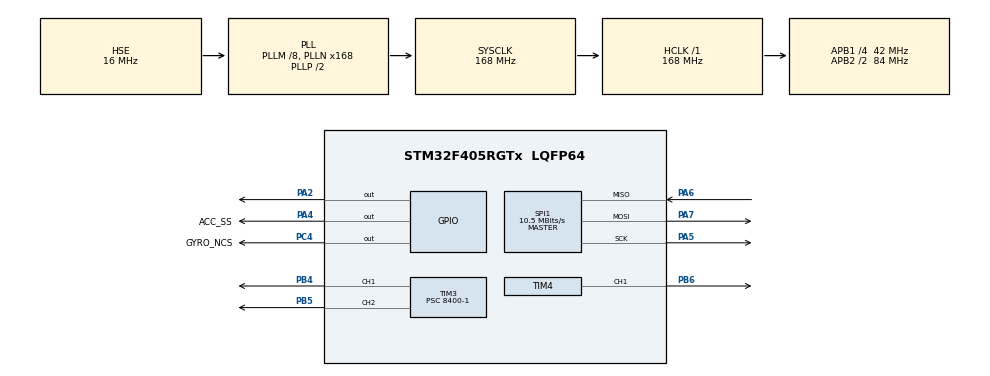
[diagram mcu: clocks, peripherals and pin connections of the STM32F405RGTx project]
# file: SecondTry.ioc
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Mcu.Family=STM32F4
Mcu.Name=STM32F405RGTx
Mcu.Package=LQFP64
NVIC.PriorityGroup=NVIC_PRIORITYGROUP_4
PA13.Mode=Trace_Asynchronous_SW
PA13.Signal=SYS_JTMS-SWDIO
PA14.Mode=Trace_Asynchronous_SW
PA14.Signal=SYS_JTCK-SWCLK
PA2.Signal=GPIO_Output
PA4.GPIO_Label=ACC_SS
PA4.Signal=GPIO_Output
PA5.Mode=Full_Duplex_Master
PA5.Signal=SPI1_SCK
PA6.Mode=Full_Duplex_Master
PA6.Signal=SPI1_MISO
PA7.Mode=Full_Duplex_Master
PA7.Signal=SPI1_MOSI
PB3.Mode=Trace_Asynchronous_SW
PB3.Signal=SYS_JTDO-SWO
PB4.Signal=S_TIM3_CH1
PB5.Signal=S_TIM3_CH2
PB6.Signal=S_TIM4_CH1
PC4.GPIO_Label=GYRO_NCS
PC4.Signal=GPIO_Output
PH0-OSC_IN.Mode=HSE-External-Oscillator
PH0-OSC_IN.Signal=RCC_OSC_IN
PH1-OSC_OUT.Mode=HSE-External-Oscillator
PH1-OSC_OUT.Signal=RCC_OSC_OUT
ProjectManager.HeapSize=0x200
ProjectManager.StackSize=0x400
ProjectManager.TargetToolchain=STM32CubeIDE
RCC.48MHZClocksFreq_Value=48000000
RCC.AHBFreq_Value=168000000
RCC.APB1CLKDivider=RCC_HCLK_DIV4
RCC.APB1Freq_Value=42000000
RCC.APB1TimFreq_Value=84000000
RCC.APB2CLKDivider=RCC_HCLK_DIV2
RCC.APB2Freq_Value=84000000
RCC.APB2TimFreq_Value=168000000
RCC.CortexFreq_Value=168000000
RCC.HCLKFreq_Value=168000000
RCC.HSE_VALUE=16000000
RCC.HSI_VALUE=16000000
RCC.LSE_VALUE=32768
RCC.PLLM=8
RCC.PLLN=168
RCC.PLLQ=7
RCC.PLLSourceVirtual=RCC_PLLSOURCE_HSE
RCC.SYSCLKFreq_VALUE=168000000
RCC.SYSCLKSource=RCC_SYSCLKSOURCE_PLLCLK
RCC.VCOOutputFreq_Value=336000000
SH.S_TIM3_CH1.0=TIM3_CH1,PWM Generation1 CH1
SH.S_TIM3_CH2.0=TIM3_CH2,PWM Generation2 CH2
SH.S_TIM4_CH1.0=TIM4_CH1,PWM Generation1 CH1
SPI1.BaudRatePrescaler=SPI_BAUDRATEPRESCALER_8
SPI1.CalculateBaudRate=10.5 MBits/s
SPI1.Direction=SPI_DIRECTION_2LINES
SPI1.Mode=SPI_MODE_MASTER
SPI1.VirtualType=VM_MASTER
TIM3.Channel-PWM\ Generation1\ CH1=TIM_CHANNEL_1
TIM3.Channel-PWM\ Generation2\ CH2=TIM_CHANNEL_2
TIM3.Period=100-1
TIM3.Prescaler=8400-1
TIM4.Channel-PWM\ Generation1\ CH1=TIM_CHANNEL_1
TIM4.Period=100-1
TIM4.Prescaler=8400-1
board=custom

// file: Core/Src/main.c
/* USER CODE BEGIN Header */
/**
  ******************************************************************************
  * @file           : main.c
  * @brief          : Main program body
  ******************************************************************************
  * @attention
  *
  * Copyright (c) 2024 STMicroelectronics.
  * All rights reserved.
  *
  * This software is licensed under terms that can be found in the LICENSE file
  * in the root directory of this software component.
  * If no LICENSE file comes with this software, it is provided AS-IS.
  *
  ******************************************************************************
  */
/* USER CODE END Header */
#include "main.h"
SPI_HandleTypeDef hspi1;

TIM_HandleTypeDef htim3;
TIM_HandleTypeDef htim4;

void SystemClock_Config(void);
static void MX_GPIO_Init(void);
static void MX_SPI1_Init(void);
static void MX_TIM3_Init(void);
static void MX_TIM4_Init(void);

// Define your pin connections
#define ENABLE_Pin GPIO_PIN_7
#define ENABLE_GPIO_Port GPIOA
#define STEP_Pin GPIO_PIN_8
#define STEP_GPIO_Port GPIOA
#define DIR_Pin GPIO_PIN_9
#define DIR_GPIO_Port GPIOA
#define MS_Pin GPIO_PIN_10
#define MS_GPIO_Port GPIOA

// Define pins
#define PWM_Pin GPIO_PIN_6
#define PWM_GPIO_Port GPIOC
#define R1_EN_Pin GPIO_PIN_11
#define R1_EN_GPIO_Port GPIOC
#define R1_IS_Pin GPIO_PIN_10
#define R1_IS_GPIO_Port GPIOC

// Function to initialize the BTS7960
void BTS7960_Init(void) {
    // Enable the motor driver by setting R1_EN high
    HAL_GPIO_WritePin(R1_EN_GPIO_Port, R1_EN_Pin, GPIO_PIN_SET);
}

// Function to set the PWM duty cycle (0 to 100%)
void Set_PWM_Duty(uint16_t duty_cycle) {
    if (duty_cycle > 100) duty_cycle = 100;  // Ensure duty cycle stays within bounds

    __HAL_TIM_SET_COMPARE(&htim3, TIM_CHANNEL_1, duty_cycle * (htim3.Init.Period + 1) / 100);  // Adjust for your timer and period
}
//
//// Function to read the current sense value (R1_IS)
//uint32_t Read_Current_Sense(void) {
//    uint32_t adc_value = 0;
//
//    // Start the ADC
//    HAL_ADC_Start(&hadc1);
//
//    // Poll for conversion
//    if (HAL_ADC_PollForConversion(&hadc1, 10) == HAL_OK) {
//        adc_value = HAL_ADC_GetValue(&hadc1);  // Get ADC value
//    }
//
//    // Stop the ADC
//    HAL_ADC_Stop(&hadc1);
//
//    return adc_value;
//}

// Delay function for precise control of motor steps (adjust as needed)
void delay_us(uint16_t us) {
    __HAL_TIM_SET_COUNTER(&htim3, 0);  // Assuming Timer 1 is configured for microsecond delay
    while (__HAL_TIM_GET_COUNTER(&htim3) < us);
}

// Function to initialize the motor
void Stepper_Init() {
    // Enable the motor by pulling the ENABLE pin low
    HAL_GPIO_WritePin(ENABLE_GPIO_Port, ENABLE_Pin, GPIO_PIN_RESET);  // Enable the motor driver (active low)

    // Set the microstep mode (for example, full-step mode)
    HAL_GPIO_WritePin(MS_GPIO_Port, MS_Pin, GPIO_PIN_RESET);  // Assuming low for full step, change as needed
}

// Function to move the motor in a specified direction and steps
void Stepper_Move(uint16_t steps, uint8_t direction, uint16_t step_delay) {
    // Set the direction (0 for one direction, 1 for the other)
    // HAL_GPIO_WritePin(DIR_GPIO_Port, DIR_Pin, direction ? GPIO_PIN_SET : GPIO_PIN_RESET);
    HAL_GPIO_WritePin(DIR_GPIO_Port, DIR_Pin,1);
    for (uint16_t i = 0; i < steps; i++) {
        // Pulse the STEP pin high then low
        //HAL_GPIO_WritePin(STEP_GPIO_Port, STEP_Pin, GPIO_PIN_SET);
        HAL_GPIO_WritePin(STEP_GPIO_Port, STEP_Pin, 0);

        HAL_Delay(1); // Delay 500 ms
  // Wait for the pulse duration
        //HAL_GPIO_WritePin(STEP_GPIO_Port, STEP_Pin, GPIO_PIN_SET);
        HAL_GPIO_WritePin(STEP_GPIO_Port, STEP_Pin, 1);

        HAL_Delay(1);  // Wait before the next step
    }
}

int main(void)
{

  /* MCU Configuration--------------------------------------------------------*/

  /* Reset of all peripherals, Initializes the Flash interface and the Systick. */
  HAL_Init();

  /* Configure the system clock */
  SystemClock_Config();

  /* Initialize all configured peripherals */
  MX_GPIO_Init();
  MX_SPI1_Init();
  MX_TIM3_Init();
  MX_TIM4_Init();

  /* Infinite loop */
  /* USER CODE BEGIN WHILE */
  HAL_TIM_PWM_Start(&htim3,TIM_CHANNEL_1);

  Stepper_Init();
//  MX_ADC1_Init();  // Assuming ADC1 for current sensing
  BTS7960_Init();

  while (1)
  {
	  Set_PWM_Duty(50);
	  HAL_GPIO_WritePin(PWM_GPIO_Port, PWM_Pin,1);

	 // Example: Read current sense value
	 //uint32_t current_sense_value = Read_Current_Sense();
    /* USER CODE END WHILE */
	  HAL_GPIO_TogglePin(GPIOA, GPIO_PIN_2); // Toggle PA2 pin
	  Stepper_Move(20, 0, 500);  // 0 for forward direction
	  HAL_Delay(50);  // Wait 1  second
//	  // Example: Move 200 steps backward
	  //Stepper_Move(20, 1, 500);  // 1 for backward direction
//	  HAL_Delay(10);  // Wait 1 second
	  HAL_Delay(50); // Delay 500 ms

  }
}

void SystemClock_Config(void)
{
  RCC_OscInitTypeDef RCC_OscInitStruct = {0};
  RCC_ClkInitTypeDef RCC_ClkInitStruct = {0};

  /** Configure the main internal regulator output voltage
  */
  __HAL_RCC_PWR_CLK_ENABLE();
  __HAL_PWR_VOLTAGESCALING_CONFIG(PWR_REGULATOR_VOLTAGE_SCALE1);

  /** Initializes the RCC Oscillators according to the specified parameters
  * in the RCC_OscInitTypeDef structure.
  */
  RCC_OscInitStruct.OscillatorType = RCC_OSCILLATORTYPE_HSE;
  RCC_OscInitStruct.HSEState = RCC_HSE_ON;
  RCC_OscInitStruct.PLL.PLLState = RCC_PLL_ON;
  RCC_OscInitStruct.PLL.PLLSource = RCC_PLLSOURCE_HSE;
  RCC_OscInitStruct.PLL.PLLM = 8;
  RCC_OscInitStruct.PLL.PLLN = 168;
  RCC_OscInitStruct.PLL.PLLP = RCC_PLLP_DIV2;
  RCC_OscInitStruct.PLL.PLLQ = 7;
  if (HAL_RCC_OscConfig(&RCC_OscInitStruct) != HAL_OK)
  {
    Error_Handler();
  }

  /** Initializes the CPU, AHB and APB buses clocks
  */
  RCC_ClkInitStruct.ClockType = RCC_CLOCKTYPE_HCLK|RCC_CLOCKTYPE_SYSCLK
                              |RCC_CLOCKTYPE_PCLK1|RCC_CLOCKTYPE_PCLK2;
  RCC_ClkInitStruct.SYSCLKSource = RCC_SYSCLKSOURCE_PLLCLK;
  RCC_ClkInitStruct.AHBCLKDivider = RCC_SYSCLK_DIV1;
  RCC_ClkInitStruct.APB1CLKDivider = RCC_HCLK_DIV4;
  RCC_ClkInitStruct.APB2CLKDivider = RCC_HCLK_DIV2;

  if (HAL_RCC_ClockConfig(&RCC_ClkInitStruct, FLASH_LATENCY_5) != HAL_OK)
  {
    Error_Handler();
  }
}

static void MX_SPI1_Init(void)
{

  /* SPI1 parameter configuration*/
  hspi1.Instance = SPI1;
  hspi1.Init.Mode = SPI_MODE_MASTER;
  hspi1.Init.Direction = SPI_DIRECTION_2LINES;
  hspi1.Init.DataSize = SPI_DATASIZE_8BIT;
  hspi1.Init.CLKPolarity = SPI_POLARITY_LOW;
  hspi1.Init.CLKPhase = SPI_PHASE_1EDGE;
  hspi1.Init.NSS = SPI_NSS_SOFT;
  hspi1.Init.BaudRatePrescaler = SPI_BAUDRATEPRESCALER_8;
  hspi1.Init.FirstBit = SPI_FIRSTBIT_MSB;
  hspi1.Init.TIMode = SPI_TIMODE_DISABLE;
  hspi1.Init.CRCCalculation = SPI_CRCCALCULATION_DISABLE;
  hspi1.Init.CRCPolynomial = 10;
  if (HAL_SPI_Init(&hspi1) != HAL_OK)
  {
    Error_Handler();
  }

}

static void MX_TIM3_Init(void)
{

  TIM_MasterConfigTypeDef sMasterConfig = {0};
  TIM_OC_InitTypeDef sConfigOC = {0};

  htim3.Instance = TIM3;
  htim3.Init.Prescaler = 8400-1;
  htim3.Init.CounterMode = TIM_COUNTERMODE_UP;
  htim3.Init.Period = 100-1;
  htim3.Init.ClockDivision = TIM_CLOCKDIVISION_DIV1;
  htim3.Init.AutoReloadPreload = TIM_AUTORELOAD_PRELOAD_DISABLE;
  if (HAL_TIM_PWM_Init(&htim3) != HAL_OK)
  {
    Error_Handler();
  }
  sMasterConfig.MasterOutputTrigger = TIM_TRGO_RESET;
  sMasterConfig.MasterSlaveMode = TIM_MASTERSLAVEMODE_DISABLE;
  if (HAL_TIMEx_MasterConfigSynchronization(&htim3, &sMasterConfig) != HAL_OK)
  {
    Error_Handler();
  }
  sConfigOC.OCMode = TIM_OCMODE_PWM1;
  sConfigOC.Pulse = 0;
  sConfigOC.OCPolarity = TIM_OCPOLARITY_HIGH;
  sConfigOC.OCFastMode = TIM_OCFAST_DISABLE;
  if (HAL_TIM_PWM_ConfigChannel(&htim3, &sConfigOC, TIM_CHANNEL_1) != HAL_OK)
  {
    Error_Handler();
  }
  if (HAL_TIM_PWM_ConfigChannel(&htim3, &sConfigOC, TIM_CHANNEL_2) != HAL_OK)
  {
    Error_Handler();
  }
  HAL_TIM_MspPostInit(&htim3);

}

static void MX_TIM4_Init(void)
{

  TIM_MasterConfigTypeDef sMasterConfig = {0};
  TIM_OC_InitTypeDef sConfigOC = {0};

  htim4.Instance = TIM4;
  htim4.Init.Prescaler = 8400-1;
  htim4.Init.CounterMode = TIM_COUNTERMODE_UP;
  htim4.Init.Period = 100-1;
  htim4.Init.ClockDivision = TIM_CLOCKDIVISION_DIV1;
  htim4.Init.AutoReloadPreload = TIM_AUTORELOAD_PRELOAD_DISABLE;
  if (HAL_TIM_PWM_Init(&htim4) != HAL_OK)
  {
    Error_Handler();
  }
  sMasterConfig.MasterOutputTrigger = TIM_TRGO_RESET;
  sMasterConfig.MasterSlaveMode = TIM_MASTERSLAVEMODE_DISABLE;
  if (HAL_TIMEx_MasterConfigSynchronization(&htim4, &sMasterConfig) != HAL_OK)
  {
    Error_Handler();
  }
  sConfigOC.OCMode = TIM_OCMODE_PWM1;
  sConfigOC.Pulse = 0;
  sConfigOC.OCPolarity = TIM_OCPOLARITY_HIGH;
  sConfigOC.OCFastMode = TIM_OCFAST_DISABLE;
  if (HAL_TIM_PWM_ConfigChannel(&htim4, &sConfigOC, TIM_CHANNEL_1) != HAL_OK)
  {
    Error_Handler();
  }
  HAL_TIM_MspPostInit(&htim4);

}

static void MX_GPIO_Init(void)
{
  GPIO_InitTypeDef GPIO_InitStruct = {0};

  /* GPIO Ports Clock Enable */
  __HAL_RCC_GPIOH_CLK_ENABLE();
  __HAL_RCC_GPIOA_CLK_ENABLE();
  __HAL_RCC_GPIOC_CLK_ENABLE();
  __HAL_RCC_GPIOB_CLK_ENABLE();

  /*Configure GPIO pin Output Level */
  HAL_GPIO_WritePin(GPIOA, GPIO_PIN_2|ACC_SS_Pin, GPIO_PIN_RESET);

  /*Configure GPIO pin Output Level */
  HAL_GPIO_WritePin(GYRO_NCS_GPIO_Port, GYRO_NCS_Pin, GPIO_PIN_RESET);

  /*Configure GPIO pins : PA2 ACC_SS_Pin */
  GPIO_InitStruct.Pin = GPIO_PIN_2|ACC_SS_Pin;
  GPIO_InitStruct.Mode = GPIO_MODE_OUTPUT_PP;
  GPIO_InitStruct.Pull = GPIO_NOPULL;
  GPIO_InitStruct.Speed = GPIO_SPEED_FREQ_LOW;
  HAL_GPIO_Init(GPIOA, &GPIO_InitStruct);

  /*Configure GPIO pin : GYRO_NCS_Pin */
  GPIO_InitStruct.Pin = GYRO_NCS_Pin;
  GPIO_InitStruct.Mode = GPIO_MODE_OUTPUT_PP;
  GPIO_InitStruct.Pull = GPIO_NOPULL;
  GPIO_InitStruct.Speed = GPIO_SPEED_FREQ_LOW;
  HAL_GPIO_Init(GYRO_NCS_GPIO_Port, &GPIO_InitStruct);

}

void Error_Handler(void)
{
  __disable_irq();
  while (1)
  {
  }
}
